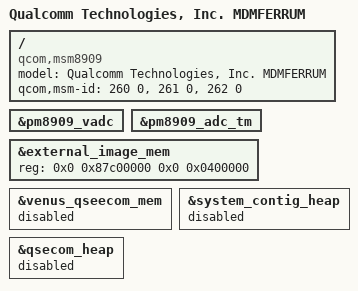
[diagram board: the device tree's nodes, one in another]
/* Copyright (c) 2014, The Linux Foundation. All rights reserved.
 *
 * This program is free software; you can redistribute it and/or modify
 * it under the terms of the GNU General Public License version 2 and
 * only version 2 as published by the Free Software Foundation.
 *
 * This program is distributed in the hope that it will be useful,
 * but WITHOUT ANY WARRANTY; without even the implied warranty of
 * MERCHANTABILITY or FITNESS FOR A PARTICULAR PURPOSE.  See the
 * GNU General Public License for more details.
 */

#include "msm8909.dtsi"
#include "msm8909-pm8909.dtsi"

/ {
	model = "Qualcomm Technologies, Inc. MDMFERRUM";
	compatible = "qcom,msm8909";
	qcom,msm-id = <260 0>, <261 0>, <262 0>;
};

&pm8909_vadc {
	/delete-node/ chan@30;
};

&pm8909_adc_tm {
	/delete-node/ chan@30;
};

&external_image_mem {
	reg = <0x0 0x87c00000 0x0 0x0400000>;
};

&venus_qseecom_mem {
	status = "disabled";
};

&system_contig_heap {
	status = "disabled";
};

&qsecom_heap {
	status = "disabled";
};

